# ADuCM350 register map
Vendor: Analog Devices; Series: ARMCM3; File version: 0.1
CPU: CM3 r2p1, little endian, no MPU, no FPU, 3 interrupt priority bits
Registers are 16-bit, access not given, no defined reset value unless marked. A register's access mark holds for its fields unless they carry their own. Offsets are from the block's base; [hi:lo] are bit positions; {n}, {i} and the like mark numbered series.

## UART
Base 0x40005000
0x00 REG_UART_COMRX 32-bit — UART Receive Buffer Register
  [0] RBR — Receive Buffer Register
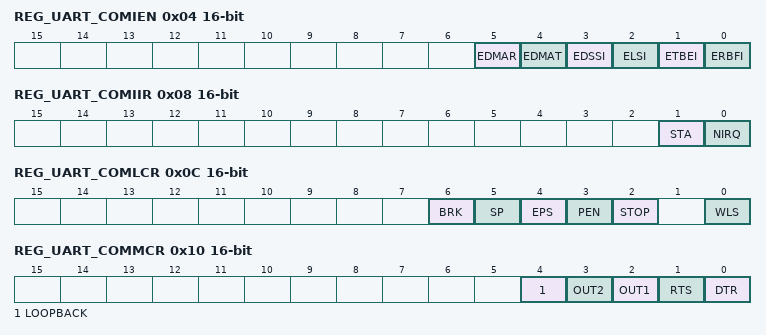
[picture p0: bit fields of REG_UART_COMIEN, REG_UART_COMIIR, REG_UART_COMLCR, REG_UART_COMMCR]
0x04 REG_UART_COMIEN — UART Interrupt Enable
  [5] EDMAR — DMA requests in transmit mode
  [4] EDMAT — DMA requests in receive mode
  [3] EDSSI — Modem status interrupt
  [2] ELSI — Rx status interrupt
  [1] ETBEI — Transmit buffer empty interrupt
  [0] ERBFI — Receive buffer full interrupt
0x08 REG_UART_COMIIR — UART Interrupt ID
  [1] STA — Interrupt status
  [0] NIRQ — Interrupt flag
0x0C REG_UART_COMLCR — UART Line Control
  [6] BRK — Set Break
  [5] SP — Stick Parity
  [4] EPS — Parity Select
  [3] PEN — Parity Enable
  [2] STOP — Stop Bit
  [0] WLS — Word Length Select
0x10 REG_UART_COMMCR — UART Modem Control
  [4] LOOPBACK — Loopback mode
  [3] OUT2 — Output 2
  [2] OUT1 — Output 1
  [1] RTS — Request to send
  [0] DTR — Data Terminal Ready
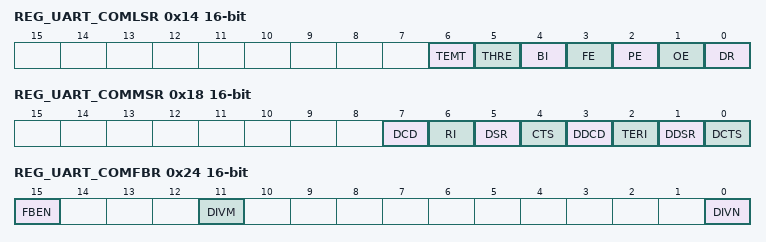
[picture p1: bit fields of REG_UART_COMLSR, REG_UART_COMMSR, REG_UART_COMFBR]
0x14 REG_UART_COMLSR — UART Line Status
  [6] TEMT — COMTX and Shift Register Empty Status
  [5] THRE — COMTX Empty
  [4] BI — Break Indicator
  [3] FE — Framing Error
  [2] PE — Parity Error
  [1] OE — Overrun Error
  [0] DR — Data Ready
0x18 REG_UART_COMMSR — UART Modem Status
  [7] DCD — Data Carrier Detect
  [6] RI — Ring Indicator
  [5] DSR — Data Set Ready
  [4] CTS — Clear To Send
  [3] DDCD — Delta DCD
  [2] TERI — Trailing Edge RI
  [1] DDSR — Delta DSR
  [0] DCTS — Delta CTS
0x1C REG_UART_COMSCR — UART Scratch buffer
  [0] SCR — Scratch
0x24 REG_UART_COMFBR — UART Fractional Baud Rate
  [15] FBEN — Fractional baud rate generator enable
  [11] DIVM — Fractional baud rate M divide bits 1 to 3
  [0] DIVN — Fractional baud rate N divide bits 0 to 2047.
0x28 REG_UART_COMDIV — UART Baudrate divider
  [15:0] VALUE

## I2S — I2S Master/Slave
Base 0x40005800
0x00 REG_I2S_I2S_OUT1L — I2S Channel 1 LSBs
  [15:8] OUT1_LSB
0x04 REG_I2S_I2S_OUT1H — I2S Channel 1 MSBs
  [15:8] OUT1_MSB
0x08 REG_I2S_I2S_OUT2L — I2S Channel 2 LSBs
  [15:8] OUT2_LSB
0x0C REG_I2S_I2S_OUT2H — I2S Channel 2 MSBs
  [15:8] OUT2_MSB
0x10 REG_I2S_I2S_MODE1 — I2S I2S format modes 1
  [15:0] VALUE
0x14 REG_I2S_I2S_MODE2 — I2S I2S format modes 2
  [15:0] VALUE
0x18 REG_I2S_I2S_CFG1 — I2S I2S configuration 1
  [15:0] VALUE
0x1C REG_I2S_I2S_CFG2 — I2S I2S configuration 2
  [15:0] VALUE
0x20 REG_I2S_I2S_STAT — I2S I2S status
  [15:0] VALUE

## BEEP — Beeper
Base 0x40005C00
0x00 REG_BEEP_BEEP_CFG — BEEP Beeper configuration
  [15:0] VALUE
0x04 REG_BEEP_BEEP_STAT — BEEP Beeper status
  [15:0] VALUE
0x08 REG_BEEP_BEEP_TONE_A — BEEP Tone A Data
  [15:0] VALUE
0x0C REG_BEEP_BEEP_TONE_B — BEEP Tone B Data
  [15:0] VALUE

## RNG — Random Bit Generator
Base 0x40006000
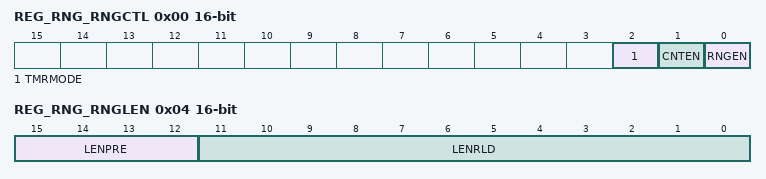
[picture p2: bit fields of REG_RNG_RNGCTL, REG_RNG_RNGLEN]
0x00 REG_RNG_RNGCTL — RNG RNG Control Register
  [2] TMRMODE — Timer Mode
  [1] CNTEN — Oscillator Counter Enable
  [0] RNGEN — RNG Enable
0x04 REG_RNG_RNGLEN — RNG RNG Sample Length Register
  [15:12] LENPRE — Prescaler for the sample counter
  [11:0] LENRLD — Reload value for the sample counter
0x08 REG_RNG_RNGSTAT — RNG RNG Status Register
  [0] RNGRDY — Random number ready
0x0C REG_RNG_RNGDATA — RNG RNG Data Register
  [15:0] VALUE
0x10 REG_RNG_RNGCNTL ro — RNG Oscillator Count Low
  [15:0] VALUE
0x14 REG_RNG_RNGCNTH ro — RNG Oscillator Count High
  [11:0] RNGCNTH — Upper bits of oscillator count

## LCD — LCD Controller
Base 0x40008000
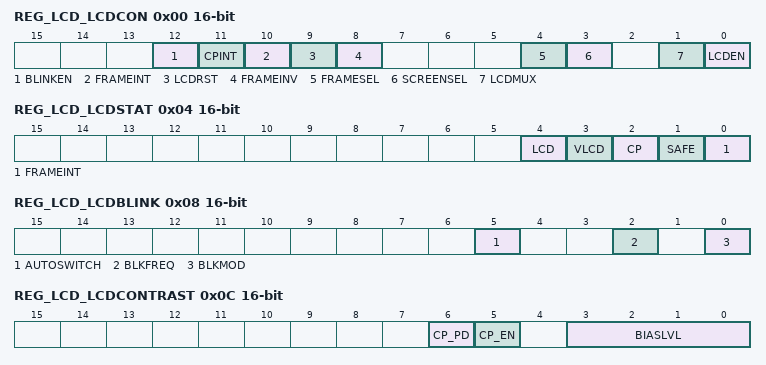
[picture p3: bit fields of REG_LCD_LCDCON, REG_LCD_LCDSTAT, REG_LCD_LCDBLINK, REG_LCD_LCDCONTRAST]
0x00 REG_LCD_LCDCON — LCD LCD Configuration Register
  [12] BLINKEN — Blink Mode Enable
  [11] CPINT — Enable Charge Pump interrupt
  [10] FRAMEINT — Enable frame boundary interrupt
  [9] LCDRST — LCD Data registers reset
  [8] FRAMEINV — Frame inversion mode enable
  [4] FRAMESEL — LCD frame rate select
  [3] SCREENSEL — Screen Select
  [1] LCDMUX — LCD Multiplex Value
  [0] LCDEN — LCD Enable
0x04 REG_LCD_LCDSTAT — LCD LCD Status Register
  [4] LCD — LCD IDLE state
  [3] VLCD — VLCD update complete
  [2] CP — Charge pump good
  [1] SAFE — Safe to write the registers
  [0] FRAMEINT — LCD Frame boundary interrupt
0x08 REG_LCD_LCDBLINK — LCD LCD Blink Control Register
  [5] AUTOSWITCH — Switch screen automatically
  [2] BLKFREQ — Blink rate configuration bits
  [0] BLKMOD — Blink mode clock source configuration bits
0x0C REG_LCD_LCDCONTRAST — LCD LCD Contrast Control Register
  [6] CP_PD — Charge pump power down
  [5] CP_EN — Charge pump enable
  [3:0] BIASLVL — Bias level selection
{0x10+4i} REG_LCD_LCDDATA{i}_S0 (i=0..7) — LCD Screen 0 LCD Data Register n
  [15:0] VALUE
{0x30+4i} REG_LCD_LCDDATA{i}_S1 (i=0..7) — LCD Screen 1 LCD Data Register n
  [15:0] VALUE
